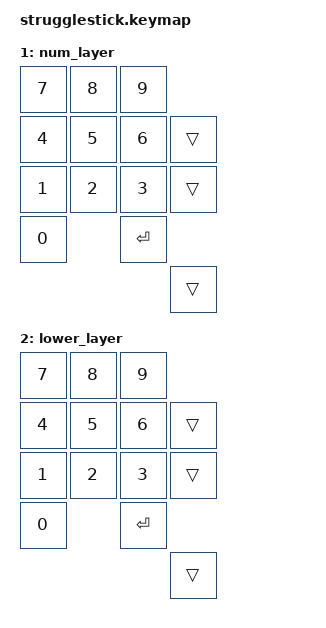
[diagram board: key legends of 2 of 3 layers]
/*
 * Copyright (c) 2020 The ZMK Contributors
 *
 * SPDX-License-Identifier: MIT
 */

#include <behaviors.dtsi>
#include <dt-bindings/zmk/keys.h>
#include <dt-bindings/zmk/bt.h>
#include <dt-bindings/zmk/mouse.h>
#include <dt-bindings/zmk/rgb.h>

/ {
    macros {
        lm: lm {
                compatible = "zmk,behavior-macro";
                wait-ms = <0>;
                tap-ms = <0>;
                #binding-cells = <0>;
                bindings
                    = <&macro_press &mo 1>
                    , <&rgb_ug RGB_COLOR_HSB(120,100,255)>
                    , <&macro_pause_for_release>
                    , <&macro_release &mo 1>
                    , <&rgb_ug RGB_COLOR_HSB(240,100,255)>;
            };
       };

    keymap {
        compatible = "zmk,keymap";
        default_layer {
            bindings = <
    &kp N7 &kp N8 &kp N9
    &kp N4 &kp N5 &kp N6 &trans
    &kp N1 &kp N2 &kp N3 &trans 
    &kp N0 &lm    &kp RETURN
                         &mkp RCLK
            >;
            sensor-bindings = <&inc_dec_kp C_VOL_UP C_VOL_DN>;
        };

        num_layer {
            bindings = <
    &kp N7 &kp N8 &kp N9
    &kp N4 &kp N5 &kp N6 &trans
    &kp N1 &kp N2 &kp N3 &trans 
    &kp N0        &kp RETURN
                         &trans 
            >; 
        };

        lower_layer {
            bindings = <
    &kp N7 &kp N8 &kp N9
    &kp N4 &kp N5 &kp N6 &trans
    &kp N1 &kp N2 &kp N3 &trans 
    &kp N0        &kp RETURN
                         &trans 
            >;
        };
    };
};
